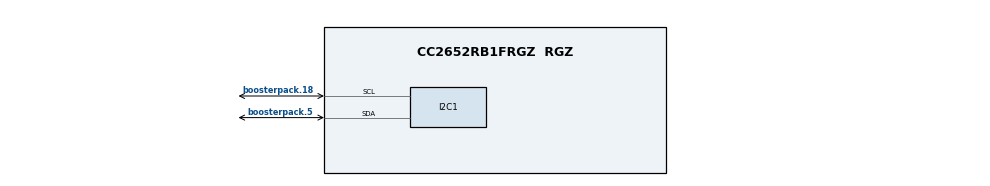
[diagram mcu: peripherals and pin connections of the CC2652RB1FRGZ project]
/**
 * @cliArgs --board "/ti/boards/LP_CC2652RB" --device "CC2652RB1FRGZ" --part "Default" --package "RGZ" --rtos "tirtos7" --product "simplelink_cc13xx_cc26xx_sdk@8.30.01.01"
 * @versions {"tool":"1.21.1+3772"}
 */
const bp_BPBASSENSORSMKII = scripting.addHardware("/ti/boards/boosterpacks/BP-BASSENSORSMKII");

/**
 * Import the modules used in this configuration.
 */
const CCFG        = scripting.addModule("/ti/devices/CCFG");
const Display     = scripting.addModule("/ti/display/Display");
const Display1    = Display.addInstance();
const GPIO        = scripting.addModule("/ti/drivers/GPIO");
const GPIO1       = GPIO.addInstance();
const GPIO2       = GPIO.addInstance();
const I2C         = scripting.addModule("/ti/drivers/I2C");
const I2C1        = I2C.addInstance();
const Settings    = scripting.addModule("/ti/posix/tirtos/Settings");
const BIOS        = scripting.addModule("/ti/sysbios/BIOS");
const Event       = scripting.addModule("/ti/sysbios/knl/Event");
const Idle        = scripting.addModule("/ti/sysbios/knl/Idle", {}, false);
const Idle2       = Idle.addInstance();
const Mailbox     = scripting.addModule("/ti/sysbios/knl/Mailbox");
const Error       = scripting.addModule("/ti/sysbios/runtime/Error");
const SysCallback = scripting.addModule("/ti/sysbios/runtime/SysCallback");
const Timestamp   = scripting.addModule("/ti/sysbios/runtime/Timestamp");

/**
 * Write custom configuration values to the imported modules.
 */
CCFG.enableBootloader         = true;
CCFG.enableBootloaderBackdoor = true;
CCFG.dioBootloaderBackdoor    = 13;
CCFG.levelBootloaderBackdoor  = "Active low";
CCFG.ccfgTemplate.$name       = "ti_devices_CCFG_CCFGCC26XXTemplate0";

Display1.$name      = "CONFIG_Display_0";
Display1.$hardware  = system.deviceData.board.components.XDS110UART;
Display1.uart.$name = "CONFIG_UART2_0";

GPIO1.$hardware = system.deviceData.board.components.LED_RED;
GPIO1.$name     = "CONFIG_GPIO_LED_0";

GPIO2.$name     = "CONFIG_GPIO_TMP_EN";
GPIO2.$hardware = bp_BPBASSENSORSMKII.components.TMP117.subComponents.POWER;

I2C1.$name              = "CONFIG_I2C_TMP";
I2C1.i2c.sdaPin.$assign = "boosterpack.5";
I2C1.i2c.sclPin.$assign = "boosterpack.18";
scripting.suppress("Connected to hardware,@@@.+?@@@ is connected to Acc/Gyro Interrupt 1 on the CC2652RB LaunchPad\\. Consider selecting it in \'use hardware\' above\\. @@@.+?@@@", I2C1.i2c, "sdaPin");
scripting.suppress("Connected to hardware,@@@.+?@@@ is connected to LaunchPad SPI Bus Chip Select on the CC2652RB LaunchPad\\. Consider selecting it in \'use hardware\' above\\. @@@.+?@@@", I2C1.i2c, "sclPin");

BIOS.assertsEnabled = false;
BIOS.heapBaseAddr   = "__primary_heap_start__";
BIOS.heapEndAddr    = "__primary_heap_end__";

const Clock      = scripting.addModule("/ti/sysbios/knl/Clock", {}, false);
Clock.tickPeriod = 10;

const Timer = scripting.addModule("/ti/sysbios/family/arm/cc26xx/Timer", {}, false);

Idle2.$name   = "powerIdle";
Idle2.idleFxn = "Power_idleFunc";

const Semaphore            = scripting.addModule("/ti/sysbios/knl/Semaphore", {}, false);
Semaphore.supportsPriority = false;

const Swi         = scripting.addModule("/ti/sysbios/knl/Swi", {}, false);
Swi.numPriorities = 6;

const Task             = scripting.addModule("/ti/sysbios/knl/Task", {}, false);
Task.checkStackFlag    = false;
Task.defaultStackSize  = 512;
Task.idleTaskStackSize = 512;
Task.numPriorities     = 6;

Error.policy       = "Error_SPIN";
Error.printDetails = false;

const System           = scripting.addModule("/ti/sysbios/runtime/System", {}, false);
System.abortFxn        = "System_abortSpin";
System.exitFxn         = "System_exitSpin";
System.extendedFormats = "%f";
System.supportModule   = "SysCallback";

/**
 * Pinmux solution for unlocked pins/peripherals. This ensures that minor changes to the automatic solver in a future
 * version of the tool will not impact the pinmux you originally saw.  These lines can be completely deleted in order to
 * re-solve from scratch.
 */
Display1.uart.uart.$suggestSolution       = "UART0";
Display1.uart.uart.txPin.$suggestSolution = "boosterpack.4";
Display1.uart.uart.rxPin.$suggestSolution = "boosterpack.3";
GPIO1.gpioPin.$suggestSolution            = "boosterpack.39";
GPIO2.gpioPin.$suggestSolution            = "boosterpack.28";
I2C1.i2c.$suggestSolution                 = "I2C0";
Timer.rtc.$suggestSolution                = "RTC0";
